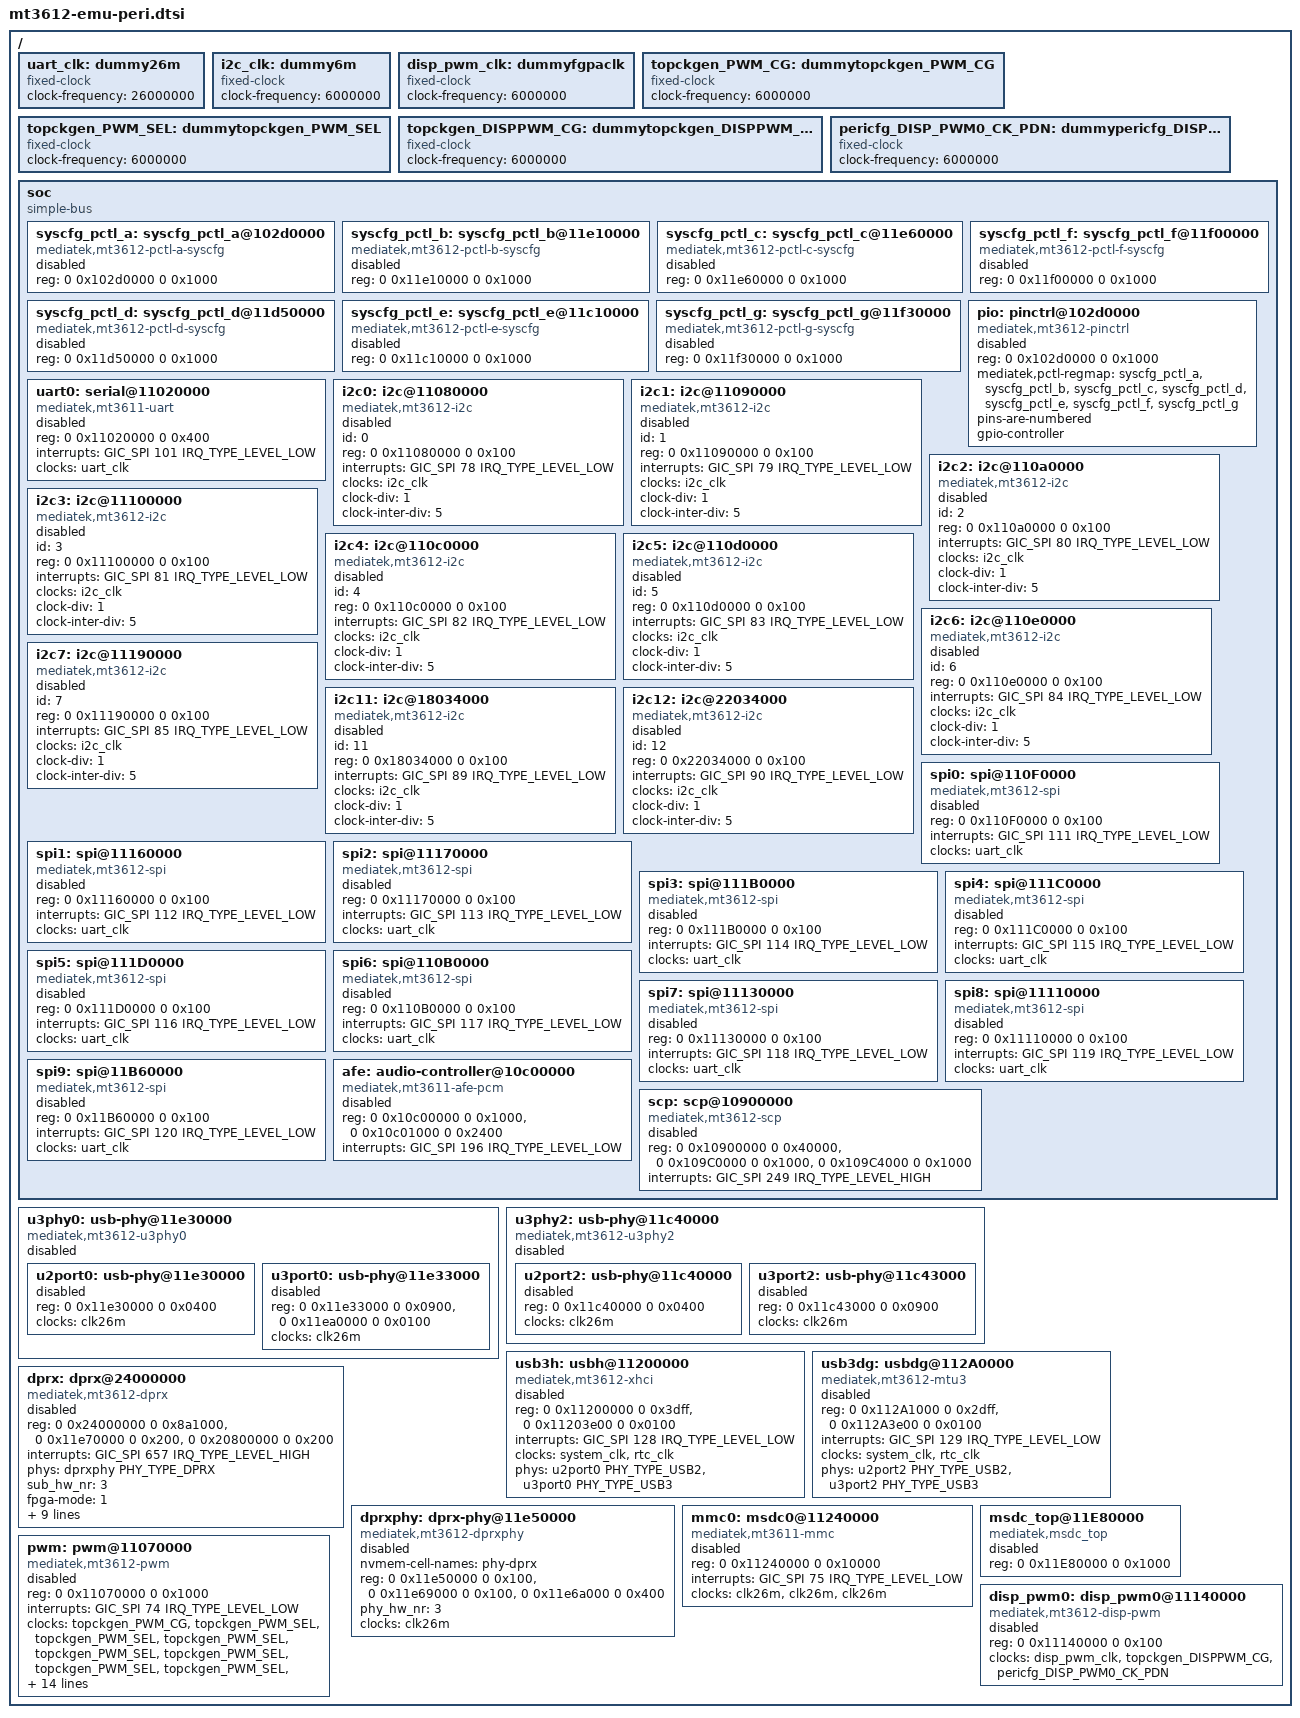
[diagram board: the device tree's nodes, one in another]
/*
 * Copyright (c) 2018 MediaTek Inc.
 * Author: Yung-Chi Chen <yung-chi.chen@mediatek.com>
 *
 * This program is free software; you can redistribute it and/or modify
 * it under the terms of the GNU General Public License version 2 as
 * published by the Free Software Foundation.
 *
 * This program is distributed in the hope that it will be useful,
 * but WITHOUT ANY WARRANTY; without even the implied warranty of
 * MERCHANTABILITY or FITNESS FOR A PARTICULAR PURPOSE.  See the
 * GNU General Public License for more details.
 */

#include <dt-bindings/interrupt-controller/arm-gic.h>
#include <dt-bindings/phy/phy.h>
#include <dt-bindings/mmc/mt3611-msdc.h>
#include "mt3612-pinfunc.h"

/ {
	uart_clk: dummy26m {
		compatible = "fixed-clock";
		clock-frequency = <26000000>;
		#clock-cells = <0>;
	};

	i2c_clk: dummy6m {
		compatible = "fixed-clock";
		clock-frequency = <6000000>;
		#clock-cells = <0>;
	};

	disp_pwm_clk: dummyfgpaclk {
		compatible = "fixed-clock";
		clock-frequency = <6000000>;
		#clock-cells = <0>;
	};

	topckgen_PWM_CG: dummytopckgen_PWM_CG {
		compatible = "fixed-clock";
		clock-frequency = <6000000>;
		#clock-cells = <0>;
	};

	topckgen_PWM_SEL: dummytopckgen_PWM_SEL {
		compatible = "fixed-clock";
		clock-frequency = <6000000>;
		#clock-cells = <0>;
	};
	topckgen_DISPPWM_CG: dummytopckgen_DISPPWM_CG {
		compatible = "fixed-clock";
		clock-frequency = <6000000>;
		#clock-cells = <0>;
	};

	pericfg_DISP_PWM0_CK_PDN: dummypericfg_DISP_PWM0_CK_PDN {
		compatible = "fixed-clock";
		clock-frequency = <6000000>;
		#clock-cells = <0>;
	};

	soc {
		#address-cells = <2>;
		#size-cells = <2>;
		compatible = "simple-bus";
		ranges;

		syscfg_pctl_a: syscfg_pctl_a@102d0000 {
			compatible = "mediatek,mt3612-pctl-a-syscfg", "syscon";
			reg = <0 0x102d0000 0 0x1000>;
			status = "disabled";
		};

		syscfg_pctl_b: syscfg_pctl_b@11e10000 {
			compatible = "mediatek,mt3612-pctl-b-syscfg", "syscon";
			reg = <0 0x11e10000 0 0x1000>;
			status = "disabled";
		};

		syscfg_pctl_c: syscfg_pctl_c@11e60000 {
			compatible = "mediatek,mt3612-pctl-c-syscfg", "syscon";
			reg = <0 0x11e60000 0 0x1000>;
			status = "disabled";
		};

		syscfg_pctl_d: syscfg_pctl_d@11d50000 {
			compatible = "mediatek,mt3612-pctl-d-syscfg", "syscon";
			reg = <0 0x11d50000 0 0x1000>;
			status = "disabled";
		};

		syscfg_pctl_e: syscfg_pctl_e@11c10000 {
			compatible = "mediatek,mt3612-pctl-e-syscfg", "syscon";
			reg = <0 0x11c10000 0 0x1000>;
			status = "disabled";
		};

		syscfg_pctl_f: syscfg_pctl_f@11f00000 {
			compatible = "mediatek,mt3612-pctl-f-syscfg", "syscon";
			reg = <0 0x11f00000 0 0x1000>;
			status = "disabled";
		};

		syscfg_pctl_g: syscfg_pctl_g@11f30000 {
			compatible = "mediatek,mt3612-pctl-g-syscfg", "syscon";
			reg = <0 0x11f30000 0 0x1000>;
			status = "disabled";
		};

		pio: pinctrl@102d0000 {
			compatible = "mediatek,mt3612-pinctrl";
			reg = <0 0x102d0000 0 0x1000>;
			mediatek,pctl-regmap = <&syscfg_pctl_a>,
					       <&syscfg_pctl_b>,
					       <&syscfg_pctl_c>,
					       <&syscfg_pctl_d>,
					       <&syscfg_pctl_e>,
					       <&syscfg_pctl_f>,
					       <&syscfg_pctl_g>;
			pins-are-numbered;
			gpio-controller;
			#gpio-cells = <2>;
			status = "disabled";
		};

		uart0: serial@11020000 {
			compatible = "mediatek,mt3611-uart";
			reg = <0 0x11020000 0 0x400>;
			interrupts = <GIC_SPI 101 IRQ_TYPE_LEVEL_LOW>;
			clocks = <&uart_clk>;
			clock-names = "baud";
			status = "disabled";
		};

		i2c0: i2c@11080000 {
			compatible = "mediatek,mt3612-i2c";
			id = <0>;
			reg = <0 0x11080000 0 0x100>;
			interrupts = <GIC_SPI 78 IRQ_TYPE_LEVEL_LOW>;
			clocks = <&i2c_clk>;
			clock-names = "main";
			clock-div = <1>;
			clock-inter-div = <5>;
			/*dmas = <&apdma 0>;*/
			dma-names = "apdma-i2c";
			#address-cells = <1>;
			#size-cells = <0>;
			status = "disabled";
		};

		i2c1: i2c@11090000 {
			compatible = "mediatek,mt3612-i2c";
			id = <1>;
			reg = <0 0x11090000 0 0x100>;
			interrupts = <GIC_SPI 79 IRQ_TYPE_LEVEL_LOW>;
			clocks = <&i2c_clk>;
			clock-names = "main";
			clock-div = <1>;
			clock-inter-div = <5>;
			/*dmas = <&apdma 1>;*/
			dma-names = "apdma-i2c";
			#address-cells = <1>;
			#size-cells = <0>;
			status = "disabled";
		};

		i2c2: i2c@110a0000 {
			compatible = "mediatek,mt3612-i2c";
			id = <2>;
			reg = <0 0x110a0000 0 0x100>;
			interrupts = <GIC_SPI 80 IRQ_TYPE_LEVEL_LOW>;
			clocks = <&i2c_clk>;
			clock-names = "main";
			clock-div = <1>;
			clock-inter-div = <5>;
			/*dmas = <&apdma 2>;*/
			dma-names = "apdma-i2c";
			#address-cells = <1>;
			#size-cells = <0>;
			status = "disabled";
		};

		i2c3: i2c@11100000 {
			compatible = "mediatek,mt3612-i2c";
			id = <3>;
			reg = <0 0x11100000 0 0x100>;
			interrupts = <GIC_SPI 81 IRQ_TYPE_LEVEL_LOW>;
			clocks = <&i2c_clk>;
			clock-names = "main";
			clock-div = <1>;
			clock-inter-div = <5>;
			/*dmas = <&apdma 3>;*/
			dma-names = "apdma-i2c";
			#address-cells = <1>;
			#size-cells = <0>;
			status = "disabled";
		};

		i2c4: i2c@110c0000 {
			compatible = "mediatek,mt3612-i2c";
			id = <4>;
			reg = <0 0x110c0000 0 0x100>;
			interrupts = <GIC_SPI 82 IRQ_TYPE_LEVEL_LOW>;
			clocks = <&i2c_clk>;
			clock-names = "main";
			clock-div = <1>;
			clock-inter-div = <5>;
			/*dmas = <&apdma 4>;*/
			dma-names = "apdma-i2c";
			#address-cells = <1>;
			#size-cells = <0>;
			status = "disabled";
		};

		i2c5: i2c@110d0000 {
			compatible = "mediatek,mt3612-i2c";
			id = <5>;
			reg = <0 0x110d0000 0 0x100>;
			interrupts = <GIC_SPI 83 IRQ_TYPE_LEVEL_LOW>;
			clocks = <&i2c_clk>;
			clock-names = "main";
			clock-div = <1>;
			clock-inter-div = <5>;
			/*dmas = <&apdma 5>;*/
			dma-names = "apdma-i2c";
			#address-cells = <1>;
			#size-cells = <0>;
			status = "disabled";
		};

		i2c6: i2c@110e0000 {
			compatible = "mediatek,mt3612-i2c";
			id = <6>;
			reg = <0 0x110e0000 0 0x100>;
			interrupts = <GIC_SPI 84 IRQ_TYPE_LEVEL_LOW>;
			clocks = <&i2c_clk>;
			clock-names = "main";
			clock-div = <1>;
			clock-inter-div = <5>;
			/*dmas = <&apdma 6>;*/
			dma-names = "apdma-i2c";
			#address-cells = <1>;
			#size-cells = <0>;
			status = "disabled";
		};

		i2c7: i2c@11190000 {
			compatible = "mediatek,mt3612-i2c";
			id = <7>;
			reg = <0 0x11190000 0 0x100>;
			interrupts = <GIC_SPI 85 IRQ_TYPE_LEVEL_LOW>;
			clocks = <&i2c_clk>;
			clock-names = "main";
			clock-div = <1>;
			clock-inter-div = <5>;
			/*dmas = <&apdma 7>;*/
			dma-names = "apdma-i2c";
			#address-cells = <1>;
			#size-cells = <0>;
			status = "disabled";
		};

		i2c11: i2c@18034000 {
			compatible = "mediatek,mt3612-i2c";
			id = <11>;
			reg = <0 0x18034000 0 0x100>;
			interrupts = <GIC_SPI 89 IRQ_TYPE_LEVEL_LOW>;
			clocks = <&i2c_clk>;
			clock-names = "main";
			clock-div = <1>;
			clock-inter-div = <5>;
			/*dmas = <&apdma 21>;*/
			dma-names = "apdma-i2c";
			#address-cells = <1>;
			#size-cells = <0>;
			status = "disabled";
		};

		i2c12: i2c@22034000 {
			compatible = "mediatek,mt3612-i2c";
			id = <12>;
			reg = <0 0x22034000 0 0x100>;
			interrupts = <GIC_SPI 90 IRQ_TYPE_LEVEL_LOW>;
			clocks = <&i2c_clk>;
			clock-names = "main";
			clock-div = <1>;
			clock-inter-div = <5>;
			/*dmas = <&apdma 22>;*/
			dma-names = "apdma-i2c";
			#address-cells = <1>;
			#size-cells = <0>;
			status = "disabled";
		};

		spi0: spi@110F0000 {
			compatible = "mediatek,mt3612-spi";
			reg = <0 0x110F0000 0 0x100>;
			interrupts = <GIC_SPI 111 IRQ_TYPE_LEVEL_LOW>;
			clocks = <&uart_clk>;
			clock-names = "spi-clk";
			#address-cells = <1>;
			#size-cells = <0>;
			status = "disabled";
		};

		spi1: spi@11160000 {
			compatible = "mediatek,mt3612-spi";
			reg = <0 0x11160000 0 0x100>;
			interrupts = <GIC_SPI 112 IRQ_TYPE_LEVEL_LOW>;
			clocks = <&uart_clk>;
			clock-names = "spi-clk";
			#address-cells = <1>;
			#size-cells = <0>;
			status = "disabled";
		};

		spi2: spi@11170000 {
			compatible = "mediatek,mt3612-spi";
			reg = <0 0x11170000 0 0x100>;
			interrupts = <GIC_SPI 113 IRQ_TYPE_LEVEL_LOW>;
			clocks = <&uart_clk>;
			clock-names = "spi-clk";
			#address-cells = <1>;
			#size-cells = <0>;
			status = "disabled";
		};

		spi3: spi@111B0000 {
			compatible = "mediatek,mt3612-spi";
			reg = <0 0x111B0000 0 0x100>;
			interrupts = <GIC_SPI 114 IRQ_TYPE_LEVEL_LOW>;
			clocks = <&uart_clk>;
			clock-names = "spi-clk";
			#address-cells = <1>;
			#size-cells = <0>;
			status = "disabled";
		};

		spi4: spi@111C0000 {
			compatible = "mediatek,mt3612-spi";
			reg = <0 0x111C0000 0 0x100>;
			interrupts = <GIC_SPI 115 IRQ_TYPE_LEVEL_LOW>;
			clocks = <&uart_clk>;
			clock-names = "spi-clk";
			#address-cells = <1>;
			#size-cells = <0>;
			status = "disabled";
		};

		spi5: spi@111D0000 {
			compatible = "mediatek,mt3612-spi";
			reg = <0 0x111D0000 0 0x100>;
			interrupts = <GIC_SPI 116 IRQ_TYPE_LEVEL_LOW>;
			clocks = <&uart_clk>;
			clock-names = "spi-clk";
			#address-cells = <1>;
			#size-cells = <0>;
			status = "disabled";
		};

		spi6: spi@110B0000 {
			compatible = "mediatek,mt3612-spi";
			reg = <0 0x110B0000 0 0x100>;
			interrupts = <GIC_SPI 117 IRQ_TYPE_LEVEL_LOW>;
			clocks = <&uart_clk>;
			clock-names = "spi-clk";
			#address-cells = <1>;
			#size-cells = <0>;
			status = "disabled";
		};

		spi7: spi@11130000 {
			compatible = "mediatek,mt3612-spi";
			reg = <0 0x11130000 0 0x100>;
			interrupts = <GIC_SPI 118 IRQ_TYPE_LEVEL_LOW>;
			clocks = <&uart_clk>;
			clock-names = "spi-clk";
			#address-cells = <1>;
			#size-cells = <0>;
			status = "disabled";
		};

		spi8: spi@11110000 {
			compatible = "mediatek,mt3612-spi";
			reg = <0 0x11110000 0 0x100>;
			interrupts = <GIC_SPI 119 IRQ_TYPE_LEVEL_LOW>;
			clocks = <&uart_clk>;
			clock-names = "spi-clk";
			#address-cells = <1>;
			#size-cells = <0>;
			status = "disabled";
		};

		spi9: spi@11B60000 {
			compatible = "mediatek,mt3612-spi";
			reg = <0 0x11B60000 0 0x100>;
			interrupts = <GIC_SPI 120 IRQ_TYPE_LEVEL_LOW>;
			clocks = <&uart_clk>;
			clock-names = "spi-clk";
			#address-cells = <1>;
			#size-cells = <0>;
			status = "disabled";
		};

		afe: audio-controller@10c00000 {
			compatible = "mediatek,mt3611-afe-pcm";
			reg = <0 0x10c00000 0 0x1000>,
			      <0 0x10c01000 0 0x2400>;
			interrupts = <GIC_SPI 196 IRQ_TYPE_LEVEL_LOW>;
			status = "disabled";
		};

		scp: scp@10900000 {
			compatible = "mediatek,mt3612-scp";
			#interrupt-cells = <3>;
			reg = <0 0x10900000 0 0x40000>,		/* sram */
			      <0 0x109C0000 0 0x1000>,		/* cfgreg */
			      <0 0x109C4000 0 0x1000>;		/* clkctrl */
			interrupts = <GIC_SPI 249 IRQ_TYPE_LEVEL_HIGH>;
			status = "disabled";
		};
	};

	u3phy0: usb-phy@11e30000 {
		compatible = "mediatek,mt3612-u3phy0";
		#address-cells = <2>;
		#size-cells = <2>;
		ranges;
		status = "disabled";

		u2port0: usb-phy@11e30000 {
			reg = <0 0x11e30000 0 0x0400>;
			clocks = <&clk26m>;
			clock-names = "ref";
			#phy-cells = <1>;
			status = "disabled";
		};

		u3port0: usb-phy@11e33000 {
			reg = <0 0x11e33000 0 0x0900>,
			      <0 0x11ea0000 0 0x0100>;
			clocks = <&clk26m>;
			clock-names = "ref";
			#phy-cells = <1>;
			status = "disabled";
		};
	};

	u3phy2: usb-phy@11c40000 {
		compatible = "mediatek,mt3612-u3phy2";
		#address-cells = <2>;
		#size-cells = <2>;
		ranges;
		status = "disabled";

		u2port2: usb-phy@11c40000 {
			reg = <0 0x11c40000 0 0x0400>;
			clocks = <&clk26m>;
			clock-names = "ref";
			#phy-cells = <1>;
			status = "disabled";
		};

		u3port2: usb-phy@11c43000 {
			reg = <0 0x11c43000 0 0x0900>;
			clocks = <&clk26m>;
			clock-names = "ref";
			#phy-cells = <1>;
			status = "disabled";
		};
	};

	usb3h: usbh@11200000 {
		compatible = "mediatek,mt3612-xhci";
		reg = <0 0x11200000 0 0x3dff>,
		      <0 0x11203e00 0 0x0100>;
		reg-names = "mac", "ippc";
		interrupts = <GIC_SPI 128 IRQ_TYPE_LEVEL_LOW>;
		clocks = <&system_clk>, <&rtc_clk>;
		clock-names = "sys_ck", "free_ck";
		phys = <&u2port0 PHY_TYPE_USB2>,
		<&u3port0 PHY_TYPE_USB3>;
		status = "disabled";
	};

	usb3dg: usbdg@112A0000 {
		compatible = "mediatek,mt3612-mtu3";
		reg = <0 0x112A1000 0 0x2dff>,
		      <0 0x112A3e00 0 0x0100>;
		reg-names = "mac", "ippc";
		interrupts = <GIC_SPI 129 IRQ_TYPE_LEVEL_LOW>;
		clocks = <&system_clk>, <&rtc_clk>;
		clock-names = "sys_ck", "free_ck";
		phys = <&u2port2 PHY_TYPE_USB2>,
		<&u3port2 PHY_TYPE_USB3>;
		status = "disabled";
	};

	dprx: dprx@24000000 {
		compatible = "mediatek,mt3612-dprx";
		reg =   <0 0x24000000 0 0x8a1000>,
			<0 0x11e70000 0 0x200>,
			<0 0x20800000 0 0x200>;
		interrupts = <GIC_SPI 657 IRQ_TYPE_LEVEL_HIGH>;
		/* power-domains = <&scpsys MT3611_POWER_DOMAIN_DP>; */
		/* clocks = <&topckgen TOPCKGEN_F26M_DP_REF_CK_EN>; */
		/* clock-names = "ref_clk"; */
		/* resets = <&toprgu MT3611_TOPRGU_DP_RST>; */
		/* reset-names = "dprx_rst";*/
		phys = <&dprxphy PHY_TYPE_DPRX>;

		sub_hw_nr = <3>;
		fpga-mode = <1>;
		hw-number = <1>;
		dprx-lanes = <4>;
		dp1p3 = <1>;
		dsc = <1>;
		fec = <1>;
		hdcp2p2 = <1>;
		yuv420 = <1>;
		audio = <1>;
		hbr3 = <1>;
		status = "disabled";
	};

	dprxphy: dprx-phy@11e50000 {
		compatible = "mediatek,mt3612-dprxphy";
		/* nvmem-cells = <&phy_hdmi_dp>; */
		nvmem-cell-names = "phy-dprx";
		reg =	<0 0x11e50000 0 0x100>,
			<0 0x11e69000 0 0x100>,
			<0 0x11e6a000 0 0x400>;
		/* power-domains = <&scpsys MT3611_POWER_DOMAIN_DP_PHY>; */
		phy_hw_nr = <3>;
		clocks = <&clk26m>;
		clock-names = "ref";
		#phy-cells = <1>;
		status = "disabled";
	 };

	mmc0: msdc0@11240000 {
		compatible = "mediatek,mt3611-mmc";
		reg = <0 0x11240000 0 0x10000>;
		interrupts = <GIC_SPI 75 IRQ_TYPE_LEVEL_LOW>;
		clocks = <&clk26m>,
			 <&clk26m>,
			 <&clk26m>;
		clock-names = "source, hclk, aesclk";
		status = "disabled";
	};

	msdc_top@11E80000 {
		compatible = "mediatek,msdc_top";
		reg = <0 0x11E80000 0 0x1000>;
		status = "disabled";
	};

	pwm: pwm@11070000 {
		compatible = "mediatek,mt3612-pwm";
		reg = <0 0x11070000 0 0x1000>;
		interrupts = <GIC_SPI 74 IRQ_TYPE_LEVEL_LOW>;
		clocks = <&topckgen_PWM_CG>,
				<&topckgen_PWM_SEL>,
				<&topckgen_PWM_SEL>,
				<&topckgen_PWM_SEL>,
				<&topckgen_PWM_SEL>,
				<&topckgen_PWM_SEL>,
				<&topckgen_PWM_SEL>,
				<&topckgen_PWM_SEL>,
				<&topckgen_PWM_SEL>,
				<&topckgen_PWM_SEL>,
				<&topckgen_PWM_SEL>,
				<&topckgen_PWM_SEL>,
				<&topckgen_PWM_SEL>,
				<&topckgen_PWM_SEL>,
				<&topckgen_PWM_SEL>,
				<&topckgen_PWM_SEL>,
				<&topckgen_PWM_SEL>,
				<&topckgen_PWM_SEL>,
				<&topckgen_PWM_SEL>,
				<&topckgen_PWM_SEL>,
				<&topckgen_PWM_SEL>,
				<&topckgen_PWM_SEL>,
				<&topckgen_PWM_SEL>,
				<&topckgen_PWM_SEL>,
				<&topckgen_PWM_SEL>,
				<&topckgen_PWM_SEL>,
				<&topckgen_PWM_SEL>,
				<&topckgen_PWM_SEL>,
				<&topckgen_PWM_SEL>,
				<&topckgen_PWM_SEL>,
				<&topckgen_PWM_SEL>,
				<&topckgen_PWM_SEL>,
				<&topckgen_PWM_SEL>,
				<&topckgen_PWM_SEL>,
				<&topckgen_PWM_SEL>;
		clock-names =   "groupclk",
			"fpwmclk",
			"pwmclk",
			"pwm1clk",
			"pwm2clk",
			"pwm3clk",
			"pwm4clk",
			"pwm5clk",
			"pwm6clk",
			"pwm7clk",
			"pwm8clk",
			"pwm9clk",
			"pwm10clk",
			"pwm11clk",
			"pwm12clk",
			"pwm13clk",
			"pwm14clk",
			"pwm15clk",
			"pwm16clk",
			"pwm17clk",
			"pwm18clk",
			"pwm19clk",
			"pwm20clk",
			"pwm21clk",
			"pwm22clk",
			"pwm23clk",
			"pwm24clk",
			"pwm25clk",
			"pwm26clk",
			"pwm27clk",
			"pwm28clk",
			"pwm29clk",
			"pwm30clk",
			"pwm31clk",
			"pwm32clk";
		status = "disabled";
	};
	disp_pwm0: disp_pwm0@11140000 {
		compatible = "mediatek,mt3612-disp-pwm";
		reg = <0 0x11140000 0 0x100>;
		clocks = <&disp_pwm_clk>,
			<&topckgen_DISPPWM_CG>,
			<&pericfg_DISP_PWM0_CK_PDN>;
		clock-names =   "main", "pwm-clk", "pwm-pericfg-clk";
		status = "disabled";
	};
};
